AUTOSAR XML (schema 00044)
package /ComponentTypes
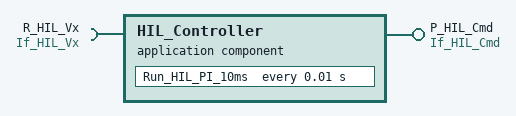
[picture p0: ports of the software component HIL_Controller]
  application sw component type HIL_Controller
    require port R_HIL_Vx: required-interface=If_HIL_Vx
      required-com-specs:
        data-element=Vx, filter=data-filter-type=ALWAYS, init-value=0
        data-element=Cnt, filter=data-filter-type=ALWAYS, init-value=0
    provide port P_HIL_Cmd: provided-interface=If_HIL_Cmd
      provided-com-specs:
        data-element=Throttle, init-value=0
        data-element=Pcon, init-value=0
        data-element=Heartbeat, init-value=0
        data-element=Fault, init-value=0
    behavior HIL_Controller_InternalBehavior
      timing event TMT_Run_HIL_PI_10ms: start-on-event=Run_HIL_PI_10ms, period=0.01
      runnable Run_HIL_PI_10ms: symbol=HIL_Controller_Run10ms
        data-receive-point-by-arguments:
          access REC_R_HIL_Vx_Cnt: accessed-variable=R_HIL_Vx.Cnt
          access REC_R_HIL_Vx_Vx: accessed-variable=R_HIL_Vx.Vx
        data-send-points:
          4 x access:
            SEND_P_HIL_Cmd_Fault: accessed-variable=P_HIL_Cmd.Fault
            SEND_P_HIL_Cmd_Heartbeat: accessed-variable=P_HIL_Cmd.Heartbeat
            SEND_P_HIL_Cmd_Pcon: accessed-variable=P_HIL_Cmd.Pcon
            SEND_P_HIL_Cmd_Throttle: accessed-variable=P_HIL_Cmd.Throttle
  swc implementation HIL_Controller_Implementation: behavior=HIL_Controller_InternalBehavior
